VERSION ""

NS_ :

BS_:

BU_:

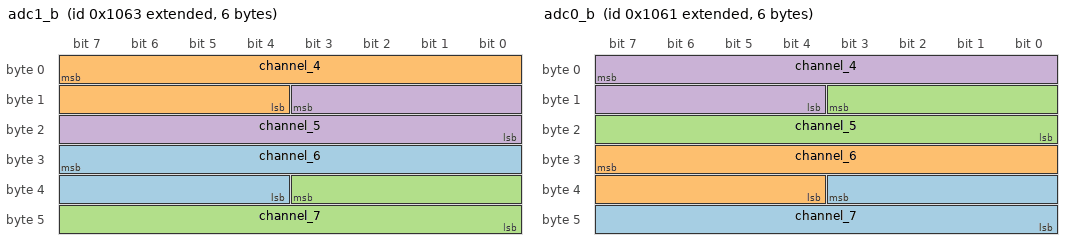
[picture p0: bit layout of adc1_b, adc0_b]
BO_ 2147487843 adc1_b: 6 Vector__XXX
 SG_ channel_6 : 31|12@0+ (1,0) [0|4095] "" Vector__XXX
 SG_ channel_4 : 7|12@0+ (1,0) [0|4095] "" Vector__XXX
 SG_ channel_7 : 35|12@0+ (1,0) [0|4095] "" Vector__XXX
 SG_ channel_5 : 11|12@0+ (1,0) [0|4095] "" Vector__XXX

BO_ 2147487841 adc0_b: 6 Vector__XXX
 SG_ channel_7 : 35|12@0+ (1,0) [0|4095] "" Vector__XXX
 SG_ channel_6 : 31|12@0+ (1,0) [0|4095] "" Vector__XXX
 SG_ channel_5 : 11|12@0+ (1,0) [0|4095] "" Vector__XXX
 SG_ channel_4 : 7|12@0+ (1,0) [0|4095] "" Vector__XXX

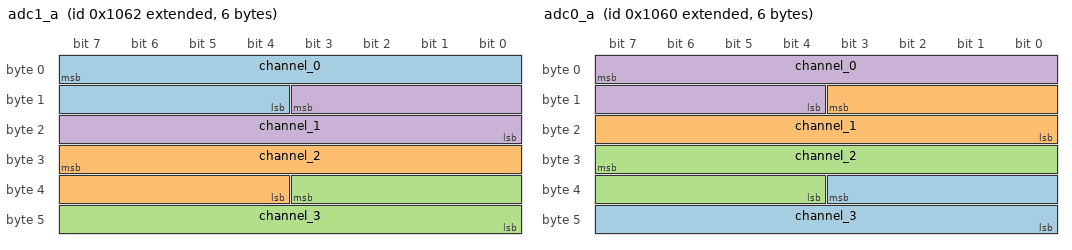
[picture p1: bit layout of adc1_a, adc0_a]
BO_ 2147487842 adc1_a: 6 Vector__XXX
 SG_ channel_0 : 7|12@0+ (1,0) [0|4095] "" Vector__XXX
 SG_ channel_2 : 31|12@0+ (1,0) [0|4095] "" Vector__XXX
 SG_ channel_3 : 35|12@0+ (1,0) [0|4095] "" Vector__XXX
 SG_ channel_1 : 11|12@0+ (1,0) [0|4095] "" Vector__XXX

BO_ 2147487840 adc0_a: 6 Vector__XXX
 SG_ channel_3 : 35|12@0+ (1,0) [0|4095] "" Vector__XXX
 SG_ channel_1 : 11|12@0+ (1,0) [0|4095] "" Vector__XXX
 SG_ channel_2 : 31|12@0+ (1,0) [0|4095] "" Vector__XXX
 SG_ channel_0 : 7|12@0+ (1,0) [0|4095] "" Vector__XXX

BA_DEF_  "BusType" STRING ;
BA_DEF_ BO_  "GenMsgCycleTime" INT 0 0;
BA_DEF_DEF_  "BusType" "CAN";
BA_DEF_DEF_  "GenMsgCycleTime" 0;
BA_ "GenMsgCycleTime" BO_ 2147487843 2;
BA_ "GenMsgCycleTime" BO_ 2147487841 2;
BA_ "GenMsgCycleTime" BO_ 2147487842 2;
BA_ "GenMsgCycleTime" BO_ 2147487840 2;
